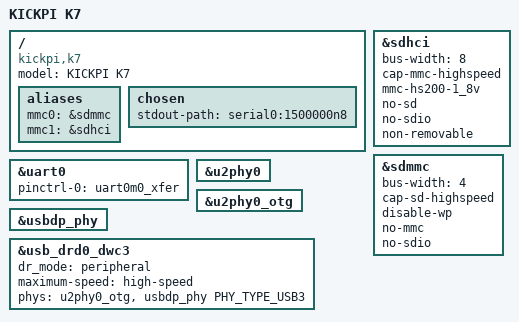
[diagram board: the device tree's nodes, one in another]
// SPDX-License-Identifier: (GPL-2.0+ OR MIT)
/*
 * Copyright 2026 Pharos Tech
 */

/dts-v1/;

#include <dt-bindings/gpio/gpio.h>
#include "rk3576.dtsi"

/ {
	model = "KICKPI K7";
	compatible = "kickpi,k7", "rockchip,rk3576";

	aliases {
		mmc0 = &sdmmc;
		mmc1 = &sdhci;
	};

	chosen {
		stdout-path = "serial0:1500000n8";
	};
};

&sdhci {
	bus-width = <8>;
	cap-mmc-highspeed;
	mmc-hs200-1_8v;
	no-sd;
	no-sdio;
	non-removable;
	status = "okay";
};

&sdmmc {
	bus-width = <4>;
	cap-sd-highspeed;
	disable-wp;
	no-mmc;
	no-sdio;
	status = "okay";
};

&uart0 {
	pinctrl-0 = <&uart0m0_xfer>;
	status = "okay";
};

&u2phy0 {
	status = "okay";
};

&u2phy0_otg {
	status = "okay";
};

&usbdp_phy {
	status = "okay";
};

&usb_drd0_dwc3 {
	dr_mode = "peripheral";
	maximum-speed = "high-speed";
	phys = <&u2phy0_otg>, <&usbdp_phy PHY_TYPE_USB3>;
	phy-names = "usb2-phy", "usb3-phy";
	status = "okay";
};
